# SMS_SECCTRL_0_SMS_TIFS_SEC_MMR_44230000h register map
Vendor: Texas Instruments
Peripheral module from a debugger description file (folder am62D).
Registers are 32-bit, read-write, reset 0x0 unless marked. A register's access mark holds for its fields unless they carry their own. Offsets are as the file gives them; lines under a group give offsets from that group; [hi:lo] are bit positions; {n}, {i} and the like mark numbered series; 'fields as' and 'values as' point back to an identical list; <NAME> marks a mode.

## SMS_TIFS_SEC_MMR
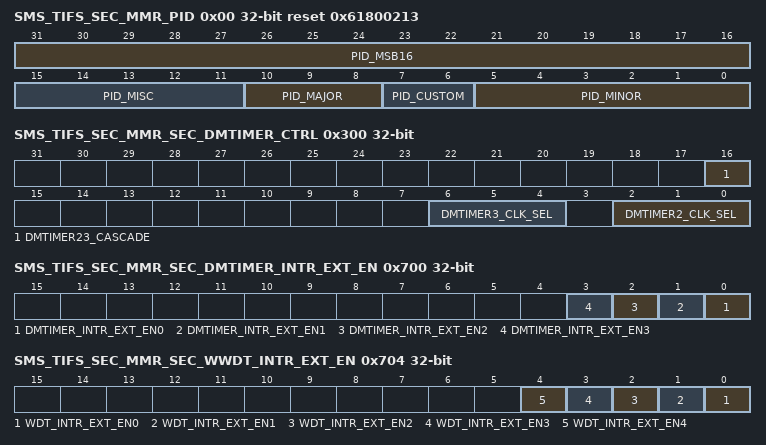
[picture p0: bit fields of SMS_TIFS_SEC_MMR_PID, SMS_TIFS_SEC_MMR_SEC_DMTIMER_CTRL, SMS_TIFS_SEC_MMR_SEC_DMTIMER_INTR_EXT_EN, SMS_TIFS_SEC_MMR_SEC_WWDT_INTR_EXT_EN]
0x00 SMS_TIFS_SEC_MMR_PID ro reset 0x61800213
  [31:16] PID_MSB16 — Reset Source: mod_g_rst_n
  [15:11] PID_MISC — Reset Source: mod_g_rst_n
  [10:8] PID_MAJOR — Reset Source: mod_g_rst_n
  [7:6] PID_CUSTOM — Reset Source: mod_g_rst_n
  [5:0] PID_MINOR — Reset Source: mod_g_rst_n
0x20 SMS_TIFS_SEC_MMR_LOCK0_KICK0
  [31:0] LOCK0_KICK0 — - KICK0 component Reset Source: mod_g_rst_n
0x24 SMS_TIFS_SEC_MMR_LOCK0_KICK1
  [31:0] LOCK0_KICK1 — - KICK1 component Reset Source: mod_g_rst_n
0x100 SMS_TIFS_SEC_MMR_SEC_ROM_START_ADDR ro
  [31:0] SEC_ROM_START_ADDR — Reset Source: mod_por_rst_n
0x104 SMS_TIFS_SEC_MMR_SEC_ROM_END_ADDR ro
  [31:0] SEC_ROM_END_ADDR — Reset Source: mod_por_rst_n
0x200 SMS_TIFS_SEC_MMR_SEC_ACTIVE
  [0] SECURITY_ACTIVE — Reset Source: mod_por_rst_n
0x210 SMS_TIFS_SEC_MMR_SEC_SOC_WARM_RESET
  [31:0] WARM_RESET_CODE — Reset Source: mod_por_rst_n
0x220 SMS_TIFS_SEC_MMR_SEC_SOC_COLD_RESET
  [31:0] COLD_RESET_CODE — Reset Source: mod_por_rst_n
0x300 SMS_TIFS_SEC_MMR_SEC_DMTIMER_CTRL
  [16] DMTIMER23_CASCADE — Reset Source: mod_por_rst_n
  [6:4] DMTIMER3_CLK_SEL — Reset Source: mod_por_rst_n
  [2:0] DMTIMER2_CLK_SEL — Reset Source: mod_por_rst_n
0x400 SMS_TIFS_SEC_MMR_SEC_EMU_WAIT_IN_RESET_REQ ro
  [0] DBG_WAIT_N_RST — Reset Source: mod_por_rst_n
0x420 SMS_TIFS_SEC_MMR_SEC_SMS_TIFS_JUMP_MAGIC_NUM
  [31:0] JUMP_MAGIC_NUM — Reset Source: mod_por_rst_n
0x430 SMS_TIFS_SEC_MMR_SEC_SMS_TIFS_JUMP_ADDRESS
  [31:0] JUMP_ADDRESS — Reset Source: mod_por_rst_n
0x500 SMS_TIFS_SEC_MMR_SEC_FW_EXP_LOWER ro
  [31:0] SEC_FW_EXP_LOW_VAL0 — Reset Source: mod_por_rst_n
0x504 SMS_TIFS_SEC_MMR_SEC_FW_EXP_UPPER ro
  [31:0] SEC_FW_EXT_UPPER_VAL0 — Reset Source: mod_por_rst_n
0x600 SMS_TIFS_SEC_MMR_SEC_CTRL_OUT0_VAL ro
  [31:0] SEC_CTRL_OUT_VAL0 — Reset Source: mod_por_rst_n
0x604 SMS_TIFS_SEC_MMR_SEC_CTRL_OUT0 access not given
  [31:0] SEC_CTRL_OUT0 — Reset Source: mod_por_rst_n (access R/W1TS)
0x608 SMS_TIFS_SEC_MMR_SEC_CTRL_OUT0_CLR access not given
  [31:0] SEC_CTRL_OUT0_CLR — Reset Source: mod_por_rst_n (access R/W1TC)
0x60C SMS_TIFS_SEC_MMR_SEC_STS_IN0 ro
  [31:0] SEC_STS_IN0 — Reset Source: mod_por_rst_n
0x700 SMS_TIFS_SEC_MMR_SEC_DMTIMER_INTR_EXT_EN
  [n] DMTIMER_INTR_EXT_EN{n} (n=0..3) — Reset Source: mod_por_rst_n
0x704 SMS_TIFS_SEC_MMR_SEC_WWDT_INTR_EXT_EN
  [n] WDT_INTR_EXT_EN{n} (n=0..4) — Reset Source: mod_por_rst_n
0x708 SMS_TIFS_SEC_MMR_SEC_DEBUG_INTR_EXT_EN
  [0] DBG_AUTH_INTR_EXT_EN0 — Reset Source: mod_por_rst_n
0x70C SMS_TIFS_SEC_MMR_SEC_ECC_AGGR_INTR_EXT_EN
  [0] ECC_AGGR_INTR_EXT_EN0 — Reset Source: mod_por_rst_n
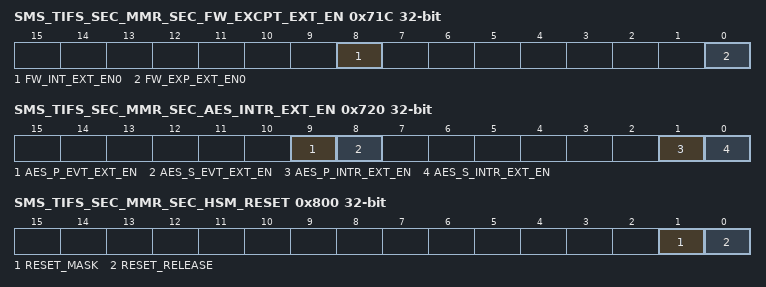
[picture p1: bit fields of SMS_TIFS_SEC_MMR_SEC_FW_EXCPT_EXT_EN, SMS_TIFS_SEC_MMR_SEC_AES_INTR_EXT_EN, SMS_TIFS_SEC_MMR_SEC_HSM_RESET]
0x71C SMS_TIFS_SEC_MMR_SEC_FW_EXCPT_EXT_EN
  [8] FW_INT_EXT_EN0 — Reset Source: mod_por_rst_n
  [0] FW_EXP_EXT_EN0 — Reset Source: mod_por_rst_n
0x720 SMS_TIFS_SEC_MMR_SEC_AES_INTR_EXT_EN
  [9] AES_P_EVT_EXT_EN — Reset Source: mod_por_rst_n
  [8] AES_S_EVT_EXT_EN — Reset Source: mod_por_rst_n
  [1] AES_P_INTR_EXT_EN — Reset Source: mod_por_rst_n
  [0] AES_S_INTR_EXT_EN — Reset Source: mod_por_rst_n
0x724 SMS_TIFS_SEC_MMR_SEC_RAT_INTR_EXT_EN
  [0] RAT_INTR_EXT_EN — Reset Source: mod_por_rst_n
0x728 SMS_TIFS_SEC_MMR_SEC_IA_INTR_EXT_EN
  [0] IA_INTR_EXT_EN — Reset Source: mod_por_rst_n
0x800 SMS_TIFS_SEC_MMR_SEC_HSM_RESET
  [1] RESET_MASK — Reset Source: mod_por_rst_n
  [0] RESET_RELEASE — Reset Source: mod_por_rst_n
0x804 SMS_TIFS_SEC_MMR_SEC_HSM_DEBUG
  [3:0] DBGEN — Reset Source: mod_por_rst_n
{0x900+4i} SMS_TIFS_SEC_MMR_SEC_SPARE_REG{i} (i=0..3)
  [31:0] SEC_SPARE{i} — Reset Source: mod_por_rst_n
